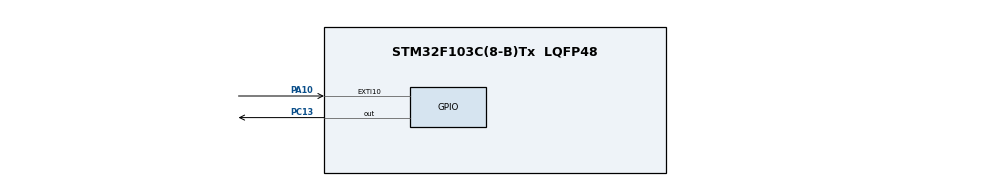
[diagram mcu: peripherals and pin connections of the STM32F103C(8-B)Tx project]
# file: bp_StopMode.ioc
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Mcu.Family=STM32F1
Mcu.Name=STM32F103C(8-B)Tx
Mcu.Package=LQFP48
NVIC.EXTI15_10_IRQn=true\:0\:0\:false\:false\:true\:true\:true
NVIC.PriorityGroup=NVIC_PRIORITYGROUP_4
PA10.GPIO_PuPd=GPIO_PULLUP
PA10.Signal=GPXTI10
PA13.Mode=Serial_Wire
PA13.Signal=SYS_JTMS-SWDIO
PA14.Mode=Serial_Wire
PA14.Signal=SYS_JTCK-SWCLK
PC13-TAMPER-RTC.Signal=GPIO_Output
ProjectManager.HeapSize=0x200
ProjectManager.StackSize=0x400
ProjectManager.TargetToolchain=STM32CubeIDE
RCC.AHBCLKDivider=RCC_SYSCLK_DIV64
RCC.AHBFreq_Value=125000
RCC.APB1Freq_Value=125000
RCC.APB1TimFreq_Value=125000
RCC.APB2Freq_Value=125000
RCC.APB2TimFreq_Value=125000
RCC.HCLKFreq_Value=125000
board=custom

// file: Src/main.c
/* USER CODE BEGIN Header */
/**
  ******************************************************************************
  * @file           : main.c
  * @brief          : Main program body
  ******************************************************************************
  * @attention
  *
  * <h2><center>&copy; Copyright (c) 2019 STMicroelectronics.
  * All rights reserved.</center></h2>
  *
  * This software component is licensed by ST under BSD 3-Clause license,
  * the "License"; You may not use this file except in compliance with the
  * License. You may obtain a copy of the License at:
  *                        opensource.org/licenses/BSD-3-Clause
  *
  ******************************************************************************
  */
/* USER CODE END Header */

#include "main.h"

void SystemClock_Config(void);
static void MX_GPIO_Init(void);

int main(void)
{

  /* MCU Configuration--------------------------------------------------------*/

  /* Reset of all peripherals, Initializes the Flash interface and the Systick. */
  HAL_Init();

  /* Configure the system clock */
  SystemClock_Config();

  /* Initialize all configured peripherals */
  MX_GPIO_Init();
  /* USER CODE BEGIN 2 */
  __HAL_RCC_PWR_CLK_ENABLE();

    HAL_GPIO_WritePin(GPIOC, GPIO_PIN_13, 0);

    HAL_Delay(5000);
    HAL_GPIO_WritePin(GPIOC, GPIO_PIN_13, 1);
  /* USER CODE END 2 */

  /* Infinite loop */
  /* USER CODE BEGIN WHILE */
  while (1)
  {
	    HAL_SuspendTick();
	    HAL_PWR_EnterSTOPMode(PWR_LOWPOWERREGULATOR_ON, PWR_SLEEPENTRY_WFI);
	    HAL_ResumeTick();
    /* USER CODE END WHILE */

  }
}

void SystemClock_Config(void)
{
  RCC_OscInitTypeDef RCC_OscInitStruct = {0};
  RCC_ClkInitTypeDef RCC_ClkInitStruct = {0};

  /** Initializes the CPU, AHB and APB busses clocks
  */
  RCC_OscInitStruct.OscillatorType = RCC_OSCILLATORTYPE_HSI;
  RCC_OscInitStruct.HSIState = RCC_HSI_ON;
  RCC_OscInitStruct.HSICalibrationValue = RCC_HSICALIBRATION_DEFAULT;
  RCC_OscInitStruct.PLL.PLLState = RCC_PLL_NONE;
  if (HAL_RCC_OscConfig(&RCC_OscInitStruct) != HAL_OK)
  {
    Error_Handler();
  }
  /** Initializes the CPU, AHB and APB busses clocks
  */
  RCC_ClkInitStruct.ClockType = RCC_CLOCKTYPE_HCLK|RCC_CLOCKTYPE_SYSCLK
                              |RCC_CLOCKTYPE_PCLK1|RCC_CLOCKTYPE_PCLK2;
  RCC_ClkInitStruct.SYSCLKSource = RCC_SYSCLKSOURCE_HSI;
  RCC_ClkInitStruct.AHBCLKDivider = RCC_SYSCLK_DIV64;
  RCC_ClkInitStruct.APB1CLKDivider = RCC_HCLK_DIV1;
  RCC_ClkInitStruct.APB2CLKDivider = RCC_HCLK_DIV1;

  if (HAL_RCC_ClockConfig(&RCC_ClkInitStruct, FLASH_LATENCY_0) != HAL_OK)
  {
    Error_Handler();
  }
}

static void MX_GPIO_Init(void)
{
  GPIO_InitTypeDef GPIO_InitStruct = {0};

  /* GPIO Ports Clock Enable */
  __HAL_RCC_GPIOC_CLK_ENABLE();
  __HAL_RCC_GPIOD_CLK_ENABLE();
  __HAL_RCC_GPIOA_CLK_ENABLE();
  __HAL_RCC_GPIOB_CLK_ENABLE();

  /*Configure GPIO pin Output Level */
  HAL_GPIO_WritePin(GPIOC, GPIO_PIN_13, GPIO_PIN_RESET);

  /*Configure GPIO pin : PC13 */
  GPIO_InitStruct.Pin = GPIO_PIN_13;
  GPIO_InitStruct.Mode = GPIO_MODE_OUTPUT_PP;
  GPIO_InitStruct.Pull = GPIO_NOPULL;
  GPIO_InitStruct.Speed = GPIO_SPEED_FREQ_LOW;
  HAL_GPIO_Init(GPIOC, &GPIO_InitStruct);

  /*Configure GPIO pins : PC14 PC15 */
  GPIO_InitStruct.Pin = GPIO_PIN_14|GPIO_PIN_15;
  GPIO_InitStruct.Mode = GPIO_MODE_ANALOG;
  HAL_GPIO_Init(GPIOC, &GPIO_InitStruct);

  /*Configure GPIO pins : PD0 PD1 */
  GPIO_InitStruct.Pin = GPIO_PIN_0|GPIO_PIN_1;
  GPIO_InitStruct.Mode = GPIO_MODE_ANALOG;
  HAL_GPIO_Init(GPIOD, &GPIO_InitStruct);

  /*Configure GPIO pins : PA0 PA1 PA2 PA3
                           PA4 PA5 PA6 PA7
                           PA8 PA9 PA11 PA12
                           PA15 */
  GPIO_InitStruct.Pin = GPIO_PIN_0|GPIO_PIN_1|GPIO_PIN_2|GPIO_PIN_3
                          |GPIO_PIN_4|GPIO_PIN_5|GPIO_PIN_6|GPIO_PIN_7
                          |GPIO_PIN_8|GPIO_PIN_9|GPIO_PIN_11|GPIO_PIN_12
                          |GPIO_PIN_15;
  GPIO_InitStruct.Mode = GPIO_MODE_ANALOG;
  HAL_GPIO_Init(GPIOA, &GPIO_InitStruct);

  /*Configure GPIO pins : PB0 PB1 PB2 PB10
                           PB11 PB12 PB13 PB14
                           PB15 PB3 PB4 PB5
                           PB6 PB7 PB8 PB9 */
  GPIO_InitStruct.Pin = GPIO_PIN_0|GPIO_PIN_1|GPIO_PIN_2|GPIO_PIN_10
                          |GPIO_PIN_11|GPIO_PIN_12|GPIO_PIN_13|GPIO_PIN_14
                          |GPIO_PIN_15|GPIO_PIN_3|GPIO_PIN_4|GPIO_PIN_5
                          |GPIO_PIN_6|GPIO_PIN_7|GPIO_PIN_8|GPIO_PIN_9;
  GPIO_InitStruct.Mode = GPIO_MODE_ANALOG;
  HAL_GPIO_Init(GPIOB, &GPIO_InitStruct);

  /*Configure GPIO pin : PA10 */
  GPIO_InitStruct.Pin = GPIO_PIN_10;
  GPIO_InitStruct.Mode = GPIO_MODE_IT_RISING;
  GPIO_InitStruct.Pull = GPIO_PULLUP;
  HAL_GPIO_Init(GPIOA, &GPIO_InitStruct);

  /*Configure peripheral I/O remapping */
  __HAL_AFIO_REMAP_PD01_ENABLE();

  /* EXTI interrupt init*/
  HAL_NVIC_SetPriority(EXTI15_10_IRQn, 0, 0);
  HAL_NVIC_EnableIRQ(EXTI15_10_IRQn);

}

/* USER CODE BEGIN 4 */
void HAL_GPIO_EXTI_Callback(uint16_t GPIO_Pin) {
	if(GPIO_Pin==GPIO_PIN_10){
		HAL_GPIO_TogglePin(GPIOC, GPIO_PIN_13);
		//HAL_TIM_PWM_Start(&htim2, TIM_CHANNEL_1);
	}
}
/* USER CODE END 4 */

void Error_Handler(void)
{
}

/************************ (C) COPYRIGHT STMicroelectronics *****END OF FILE****/
